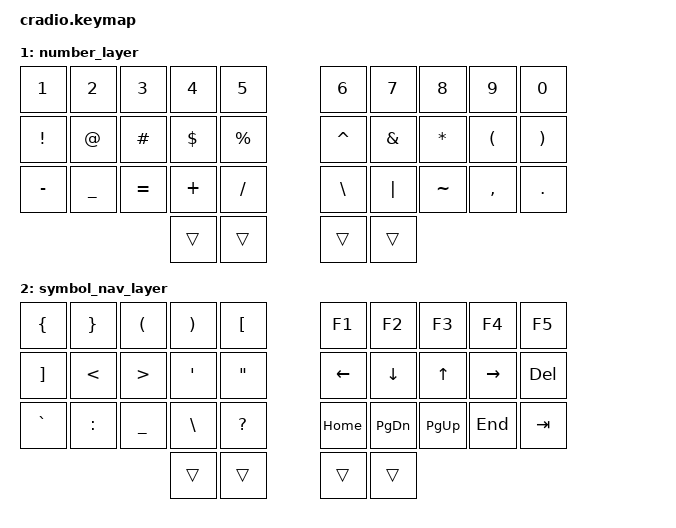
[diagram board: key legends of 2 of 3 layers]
// Ferris Sweep — ZMK keymap (2x nice!nano v2)
// Layer 0: basis (bogstaver + home row mods)
// Layer 1: tal og matematik (hold venstre tommel: ESC)
// Layer 2: symboler og navigation (hold højre tommel: BSPC)

#include <behaviors.dtsi>
#include <dt-bindings/zmk/keys.h>
#include <dt-bindings/zmk/bt.h>

// Home row mods: pinky=gui, ring=alt, middle=ctrl, index=shift
#define HRML(k1,k2,k3,k4) &hm LGUI k1  &hm LALT k2  &hm LCTRL k3  &hm LSHFT k4
#define HRMR(k1,k2,k3,k4) &hm RSHFT k1  &hm RCTRL k2  &hm RALT k3  &hm RGUI k4

/ {
    behaviors {
        hm: home_row_mod {
            compatible = "zmk,behavior-hold-tap";
            #binding-cells = <2>;
            flavor = "balanced";
            tapping-term-ms = <200>;
            quick-tap-ms = <150>;
            require-prior-idle-ms = <150>;
            bindings = <&kp>, <&kp>;
        };
    };

    keymap {
        compatible = "zmk,keymap";

        // Lag 0 – basis (bogstaver + home row mods)
        default_layer {
            bindings = <
        //╭──────────┬──────────┬──────────┬──────────┬──────────╮   ╭──────────┬──────────┬──────────┬──────────┬──────────╮
        //│  Q       │  W       │  E       │  R       │  T       │   │  Y       │  U       │  I       │  O       │  P       │
            &kp Q      &kp W      &kp E      &kp R      &kp T          &kp Y      &kp U      &kp I      &kp O      &kp P
        //├──────────┼──────────┼──────────┼──────────┼──────────┤   ├──────────┼──────────┼──────────┼──────────┼──────────┤
        //│  A gui   │  S alt   │  D ctrl  │  F shift │  G       │   │  H       │  J shift │  K ctrl  │  L alt   │  ; gui   │
            HRML(A,        S,         D,         F)     &kp G          &kp H      HRMR(J,        K,         L,        SEMI)
        //├──────────┼──────────┼──────────┼──────────┼──────────┤   ├──────────┼──────────┼──────────┼──────────┼──────────┤
        //│  Z       │  X       │  C       │  V       │  B       │   │  N       │  M       │ , <      │ . >      │ / ?      │
            &kp Z      &kp X      &kp C      &kp V      &kp B          &kp N      &kp M      &kp COMMA  &kp DOT    &kp FSLH
        //╰──────────┴──────────┴──────────┼──────────┼──────────┤   ├──────────┼──────────┼──────────┴──────────┴──────────╯
        //                                 │ ESC/L1   │  SPACE   │   │  ENTER   │ BSPC/L2  │
                                            &lt 1 ESC   &kp SPACE     &kp ENTER  &lt 2 BSPC
        //                                 ╰──────────┴──────────╯   ╰──────────┴──────────╯
            >;
        };

        // Lag 1 – tal og matematik (hold venstre tommel)
        number_layer {
            bindings = <
        //╭──────────┬──────────┬──────────┬──────────┬──────────╮   ╭──────────┬──────────┬──────────┬──────────┬──────────╮
        //│  1       │  2       │  3       │  4       │  5       │   │  6       │  7       │  8       │  9       │  0       │
            &kp N1     &kp N2     &kp N3     &kp N4     &kp N5         &kp N6     &kp N7     &kp N8     &kp N9     &kp N0
        //├──────────┼──────────┼──────────┼──────────┼──────────┤   ├──────────┼──────────┼──────────┼──────────┼──────────┤
        //│  !       │  @       │  #       │  $       │  %       │   │  ^       │  &       │  *       │  (       │  )       │
            &kp EXCL   &kp AT     &kp HASH   &kp DLLR   &kp PRCNT      &kp CARET  &kp AMPS   &kp ASTRK  &kp LPAR   &kp RPAR
        //├──────────┼──────────┼──────────┼──────────┼──────────┤   ├──────────┼──────────┼──────────┼──────────┼──────────┤
        //│  -       │  _       │  =       │  +       │  /       │   │  \       │  |       │  ~       │  ,       │  .       │
            &kp MINUS  &kp UNDER  &kp EQUAL  &kp PLUS   &kp FSLH       &kp BSLH   &kp PIPE   &kp TILDE  &kp COMMA  &kp DOT
        //╰──────────┴──────────┴──────────┼──────────┼──────────┤   ├──────────┼──────────┼──────────┴──────────┴──────────╯
                                             &trans     &trans         &trans     &trans
        //                                 ╰──────────┴──────────╯   ╰──────────┴──────────╯
            >;
        };

        // Lag 2 – symboler og navigation (hold højre tommel)
        symbol_nav_layer {
            bindings = <
        //╭──────────┬──────────┬──────────┬──────────┬──────────╮   ╭──────────┬──────────┬──────────┬──────────┬──────────╮
        //│  {       │  }       │  (       │  )       │  [       │   │  F1      │  F2      │  F3      │  F4      │  F5      │
            &kp LBRC   &kp RBRC   &kp LPAR   &kp RPAR   &kp LBKT       &kp F1     &kp F2     &kp F3     &kp F4     &kp F5
        //├──────────┼──────────┼──────────┼──────────┼──────────┤   ├──────────┼──────────┼──────────┼──────────┼──────────┤
        //│  ]       │  <       │  >       │  '       │  "       │   │  ←       │  ↓       │  ↑       │  →       │  DEL     │
            &kp RBKT   &kp LT     &kp GT     &kp SQT    &kp DQT        &kp LEFT   &kp DOWN   &kp UP     &kp RIGHT  &kp DEL
        //├──────────┼──────────┼──────────┼──────────┼──────────┤   ├──────────┼──────────┼──────────┼──────────┼──────────┤
        //│  `       │  :       │  _       │  \       │  ?       │   │  HOME    │  PGDN    │  PGUP    │  END     │  TAB     │
            &kp GRAVE  &kp COLON  &kp UNDER  &kp BSLH   &kp QMARK      &kp HOME   &kp PG_DN  &kp PG_UP  &kp END    &kp TAB
        //╰──────────┴──────────┴──────────┼──────────┼──────────┤   ├──────────┼──────────┼──────────┴──────────┴──────────╯
                                             &trans     &trans         &trans     &trans
        //                                 ╰──────────┴──────────╯   ╰──────────┴──────────╯
            >;
        };
    };
};
